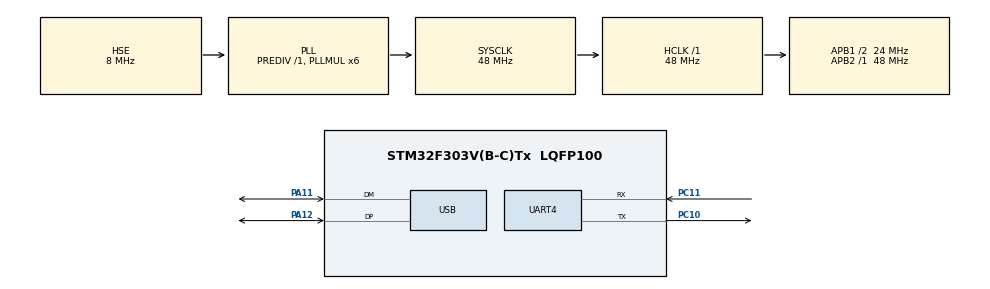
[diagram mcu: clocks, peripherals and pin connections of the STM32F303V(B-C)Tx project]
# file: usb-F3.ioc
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Mcu.Family=STM32F3
Mcu.Name=STM32F303V(B-C)Tx
Mcu.Package=LQFP100
NVIC.PriorityGroup=NVIC_PRIORITYGROUP_4
NVIC.USB_LP_CAN_RX0_IRQn=true\:0\:0\:false\:false\:true
PA11.Mode=Device
PA11.Signal=USB_DM
PA12.Mode=Device
PA12.Signal=USB_DP
PC10.Mode=Asynchronous
PC10.Signal=UART4_TX
PC11.Mode=Asynchronous
PC11.Signal=UART4_RX
PF0-OSC_IN.Mode=HSE-External-Oscillator
PF0-OSC_IN.Signal=RCC_OSC_IN
PF1-OSC_OUT.Mode=HSE-External-Oscillator
PF1-OSC_OUT.Signal=RCC_OSC_OUT
ProjectManager.HeapSize=0x200
ProjectManager.StackSize=0x400
ProjectManager.TargetToolchain=EWARM
RCC.AHBFreq_Value=48000000
RCC.APB1CLKDivider=RCC_HCLK_DIV2
RCC.APB1Freq_Value=24000000
RCC.APB1TimFreq_Value=48000000
RCC.APB2Freq_Value=48000000
RCC.APB2TimFreq_Value=48000000
RCC.CortexFreq_Value=48000000
RCC.HCLKFreq_Value=48000000
RCC.HSE_VALUE=8000000
RCC.HSIState=RCC_HSI_ON
RCC.HSI_VALUE=8000000
RCC.LSE_VALUE=32768
RCC.PLLMUL=RCC_PLL_MUL6
RCC.SYSCLKFreq_VALUE=48000000
RCC.SYSCLKSourceVirtual=RCC_SYSCLKSOURCE_PLLCLK
RCC.USBFreq_Value=48000000
USB_DEVICE.USBD_HandleTypeDef=hUsbDeviceFS
USB_DEVICE.VirtualMode=Hid
USB_DEVICE.VirtualModeFS=Hid_FS
VP_USB_DEVICE_VS_USB_DEVICE_HID_FS.Mode=HID_FS
board=usb-F3

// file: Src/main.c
/**
  ******************************************************************************
  * File Name          : main.c
  * Description        : Main program body
  ******************************************************************************
  *
  * COPYRIGHT(c) 2016 STMicroelectronics
  *
  * Redistribution and use in source and binary forms, with or without modification,
  * are permitted provided that the following conditions are met:
  *   1. Redistributions of source code must retain the above copyright notice,
  *      this list of conditions and the following disclaimer.
  *   2. Redistributions in binary form must reproduce the above copyright notice,
  *      this list of conditions and the following disclaimer in the documentation
  *      and/or other materials provided with the distribution.
  *   3. Neither the name of STMicroelectronics nor the names of its contributors
  *      may be used to endorse or promote products derived from this software
  *      without specific prior written permission.
  *
  * THIS SOFTWARE IS PROVIDED BY THE COPYRIGHT HOLDERS AND CONTRIBUTORS "AS IS"
  * AND ANY EXPRESS OR IMPLIED WARRANTIES, INCLUDING, BUT NOT LIMITED TO, THE
  * IMPLIED WARRANTIES OF MERCHANTABILITY AND FITNESS FOR A PARTICULAR PURPOSE ARE
  * DISCLAIMED. IN NO EVENT SHALL THE COPYRIGHT HOLDER OR CONTRIBUTORS BE LIABLE
  * FOR ANY DIRECT, INDIRECT, INCIDENTAL, SPECIAL, EXEMPLARY, OR CONSEQUENTIAL
  * DAMAGES (INCLUDING, BUT NOT LIMITED TO, PROCUREMENT OF SUBSTITUTE GOODS OR
  * SERVICES; LOSS OF USE, DATA, OR PROFITS; OR BUSINESS INTERRUPTION) HOWEVER
  * CAUSED AND ON ANY THEORY OF LIABILITY, WHETHER IN CONTRACT, STRICT LIABILITY,
  * OR TORT (INCLUDING NEGLIGENCE OR OTHERWISE) ARISING IN ANY WAY OUT OF THE USE
  * OF THIS SOFTWARE, EVEN IF ADVISED OF THE POSSIBILITY OF SUCH DAMAGE.
  *
  ******************************************************************************
  */
#include "stm32f3xx_hal.h"
#include "usb_device.h"
#include "usb_keyboard.h"
#include "stdbool.h"

UART_HandleTypeDef huart4;

/* USER CODE BEGIN PV */
/* Private variables ---------------------------------------------------------*/

/* USER CODE END PV */

void SystemClock_Config(void);
void Error_Handler(void);
static void MX_GPIO_Init(void);
static void MX_UART4_Init(void);

/* USER CODE BEGIN PFP */
/* Private function prototypes -----------------------------------------------*/

/* USER CODE END PFP */

inline bool usrButtonPressed()
{
  return HAL_GPIO_ReadPin(GPIOA, GPIO_PIN_0) == GPIO_PIN_SET;
}

inline void setGreenLedState(uint8_t state)
{
  HAL_GPIO_WritePin(GPIOE, GPIO_PIN_15, state == 0 ? GPIO_PIN_RESET : GPIO_PIN_SET);
}

int main(void)
{

  /* MCU Configuration----------------------------------------------------------*/

  /* Reset of all peripherals, Initializes the Flash interface and the Systick. */
  HAL_Init();

  /* Configure the system clock */
  SystemClock_Config();

  /* Initialize all configured peripherals */
  MX_GPIO_Init();
  MX_UART4_Init();
  MX_USB_DEVICE_Init();

  /* Infinite loop */
  /* USER CODE BEGIN WHILE */

  bool buttonWasPressed = false;
  while (1)
  {
  /* USER CODE END WHILE */
  const bool btnPressed = usrButtonPressed();
  if (btnPressed && !buttonWasPressed)
  {
    setGreenLedState(1);
    USB_Send_Key_Press(4, 0);
    HAL_Delay(50);
  }
  else if (!btnPressed && buttonWasPressed)
  {
    setGreenLedState(0);
    USB_Send_All_Keys_Released();
    HAL_Delay(50);
  }

  buttonWasPressed = btnPressed;

  }

}

/** System Clock Configuration
*/
void SystemClock_Config(void)
{

  RCC_OscInitTypeDef RCC_OscInitStruct;
  RCC_ClkInitTypeDef RCC_ClkInitStruct;
  RCC_PeriphCLKInitTypeDef PeriphClkInit;

  RCC_OscInitStruct.OscillatorType = RCC_OSCILLATORTYPE_HSE;
  RCC_OscInitStruct.HSEState = RCC_HSE_ON;
  RCC_OscInitStruct.HSEPredivValue = RCC_HSE_PREDIV_DIV1;
  RCC_OscInitStruct.PLL.PLLState = RCC_PLL_ON;
  RCC_OscInitStruct.PLL.PLLSource = RCC_PLLSOURCE_HSE;
  RCC_OscInitStruct.PLL.PLLMUL = RCC_PLL_MUL6;
  if (HAL_RCC_OscConfig(&RCC_OscInitStruct) != HAL_OK)
  {
    Error_Handler();
  }

  RCC_ClkInitStruct.ClockType = RCC_CLOCKTYPE_HCLK|RCC_CLOCKTYPE_SYSCLK
                              |RCC_CLOCKTYPE_PCLK1|RCC_CLOCKTYPE_PCLK2;
  RCC_ClkInitStruct.SYSCLKSource = RCC_SYSCLKSOURCE_PLLCLK;
  RCC_ClkInitStruct.AHBCLKDivider = RCC_SYSCLK_DIV1;
  RCC_ClkInitStruct.APB1CLKDivider = RCC_HCLK_DIV2;
  RCC_ClkInitStruct.APB2CLKDivider = RCC_HCLK_DIV1;
  if (HAL_RCC_ClockConfig(&RCC_ClkInitStruct, FLASH_LATENCY_1) != HAL_OK)
  {
    Error_Handler();
  }

  PeriphClkInit.PeriphClockSelection = RCC_PERIPHCLK_USB|RCC_PERIPHCLK_UART4;
  PeriphClkInit.Uart4ClockSelection = RCC_UART4CLKSOURCE_PCLK1;
  PeriphClkInit.USBClockSelection = RCC_USBCLKSOURCE_PLL;
  if (HAL_RCCEx_PeriphCLKConfig(&PeriphClkInit) != HAL_OK)
  {
    Error_Handler();
  }

  HAL_SYSTICK_Config(HAL_RCC_GetHCLKFreq()/1000);

  HAL_SYSTICK_CLKSourceConfig(SYSTICK_CLKSOURCE_HCLK);

  /* SysTick_IRQn interrupt configuration */
  HAL_NVIC_SetPriority(SysTick_IRQn, 0, 0);
}

/* UART4 init function */
static void MX_UART4_Init(void)
{

  huart4.Instance = UART4;
  huart4.Init.BaudRate = 115200;
  huart4.Init.WordLength = UART_WORDLENGTH_8B;
  huart4.Init.StopBits = UART_STOPBITS_1;
  huart4.Init.Parity = UART_PARITY_NONE;
  huart4.Init.Mode = UART_MODE_TX_RX;
  huart4.Init.HwFlowCtl = UART_HWCONTROL_NONE;
  huart4.Init.OverSampling = UART_OVERSAMPLING_16;
  huart4.Init.OneBitSampling = UART_ONE_BIT_SAMPLE_DISABLE;
  huart4.AdvancedInit.AdvFeatureInit = UART_ADVFEATURE_NO_INIT;
  if (HAL_UART_Init(&huart4) != HAL_OK)
  {
    Error_Handler();
  }

}

/** Configure pins as
        * Analog
        * Input
        * Output
        * EVENT_OUT
        * EXTI
*/
static void MX_GPIO_Init(void)
{
  /* GPIO Ports Clock Enable */
  __HAL_RCC_GPIOE_CLK_ENABLE();
  __HAL_RCC_GPIOC_CLK_ENABLE();
  __HAL_RCC_GPIOF_CLK_ENABLE();
  __HAL_RCC_GPIOA_CLK_ENABLE();
  __HAL_RCC_GPIOB_CLK_ENABLE();

  GPIO_InitTypeDef GPIOA_InitStruct;
  GPIOA_InitStruct.Pin = GPIO_PIN_0;
  GPIOA_InitStruct.Mode = GPIO_MODE_INPUT;
  GPIOA_InitStruct.Pull = GPIO_PULLDOWN;
  GPIOA_InitStruct.Speed = GPIO_SPEED_FREQ_LOW;
  HAL_GPIO_Init(GPIOA, &GPIOA_InitStruct);

  GPIO_InitTypeDef GPIOE_InitStruct;
  GPIOE_InitStruct.Pin = LD4_Pin|LD3_Pin|LD5_Pin
                          |LD7_Pin|LD9_Pin|LD10_Pin|LD8_Pin
                          |LD6_Pin;
  GPIOE_InitStruct.Mode = GPIO_MODE_OUTPUT_PP;
  GPIOE_InitStruct.Pull = GPIO_NOPULL;
  GPIOE_InitStruct.Speed = GPIO_SPEED_FREQ_LOW;
  HAL_GPIO_Init(GPIOE, &GPIOE_InitStruct);

  /*Configure GPIO pin Output Level */
  HAL_GPIO_WritePin(GPIOE, LD4_Pin|LD3_Pin|LD5_Pin
                          |LD7_Pin|LD9_Pin|LD10_Pin|LD8_Pin
                          |LD6_Pin, GPIO_PIN_RESET);
}

void Error_Handler(void)
{
  while(1)
  {
  }
}

/************************ (C) COPYRIGHT STMicroelectronics *****END OF FILE****/
